# H5 register map
Vendor: Allwinner; Series: H5; File version: 0.1
CPU: 0, little endian, MPU, no FPU, 0 interrupt priority bits
Registers are 32-bit, read-write, reset 0x0 unless marked. A register's access mark holds for its fields unless they carry their own. Offsets are from the block's base; [hi:lo] are bit positions.

## CIR
Base 0x01F02000
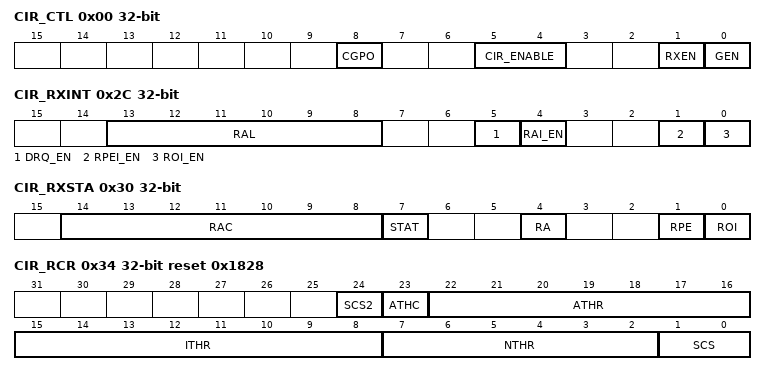
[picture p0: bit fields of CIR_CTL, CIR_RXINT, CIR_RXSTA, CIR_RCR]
0x00 CIR_CTL — CIR Control Register
  [8] CGPO — General Program Output (GPO) Control in CIR mode for TX Pin 0: Low level 1: High level
    0=Low_level; 1=High_level
  [5:4] CIR_ENABLE — 00~10: Reserved 11: CIR mode enable
    3=CIR mode enable
  [1] RXEN — Receiver Block Enable 0: Disable 1: Enable
    0=Disable; 1=Enable
  [0] GEN — Global Enable A disable on this bit overrides any other block or channel enables and flushes all FIFOs. 0: Disable 1: Enable
    0=Disable; 1=Enable
0x10 CIR_RXCTL reset 0x4 — CIR Receiver Configure Register
  [2] RPPI — Receiver Pulse Polarity Invert 0: Not invert receiver signal 1: Invert receiver signal
    0=Not invert receiver signal; 1=Invert receiver signal
0x20 CIR_RXFIFO — CIR Receiver FIFO Register
  [7:0] RECEIVER ro — Receiver Byte FIFO
0x2C CIR_RXINT — CIR Receiver Interrupt Control Register
  [13:8] RAL — RX FIFO Available Received Byte Level for interrupt and DMA request TRIGGER_LEVEL = RAL + 1
  [5] DRQ_EN — RX FIFO DMA Enable 0: Disable 1: Enable Whe set to , the Re ei e FIFO DRQ is asse ted if ea hi g RAL . The DRQ is de-asserted when condition fails.
    0=Disable; 1=Enable Whe set to , the Re ei e FIFO DRQ is asse ted if ea hi g RAL . The DRQ is de-asserted when condition fails.
  [4] RAI_EN — RX FIFO Available Interrupt Enable 0: Disable 1: Enable Whe set to , the Re ei e FIFO IRQ is asse ted if ea hi g RAL . The IRQ is de-asserted when condition fails.
    0=Disable; 1=Enable Whe set to , the Re ei e FIFO IRQ is asse ted if ea hi g RAL . The IRQ is de-asserted when condition fails.
  [1] RPEI_EN — Receiver Packet End Interrupt Enable 0: Disable 1: Enable
    0=Disable; 1=Enable
  [0] ROI_EN — Receiver FIFO Overrun Interrupt Enable 0: Disable 1: Enable
    0=Disable; 1=Enable
0x30 CIR_RXSTA — CIR Receiver Status Register
  [14:8] RAC ro — RX FIFO Available Counter 0000000: No available data in RX FIFO 0000001: 1 byte available data in RX FIFO 0000010: 2 byte available data in RX FIFO ... 1000000: 64 byte available data in RX FIFO
    0=No available data in RX FIFO; 1=1 byte available data in RX FIFO; 2=2 byte available data in RX FIFO ; 64=64 byte available data in RX FIFO
  [7] STAT ro — Status of CIR 0: Idle 1: Busy
    0=Idle; 1=Busy
  [4] RA write-1-clears — RX FIFO Available 0: RX FIFO not available according its level 1: RX FIFO available according its level This it is lea ed iti g a .
    0=RX_FIFO (RX FIFO not available according its level); 1=RX FIFO available according its level This it is lea ed iti g a 
  [1] RPE write-1-clears — Receiver Packet End Flag 0: One CIR symbol is receiving or not detected. 1: One CIR symbol is received. This it is lea ed iti g a .
    0=receiving (One CIR symbol is receiving or not detected.); 1=received (One CIR symbol is received. This it is lea ed iti g a .)
  [0] ROI write-1-clears — Receiver FIFO Overrun 0: Receiver FIFO not overrun 1: Receiver FIFO overrun This it is lea ed iti g a .
    0=Receiver_FIFO_not_overrun; 1=Receiver FIFO overrun This it is lea ed iti g a 
0x34 CIR_RCR reset 0x1828
  [24] SCS2 — Bit2 of Sample Clock Select for CIR This bit is defined by SCS bits below.
  [23] ATHC — Active Threshold Control for CIR 0: ATHR in Unit of (Sample Clock) 1: ATHR in Unit of (128*Sample Clocks)
    0=ATHR_in_Unit_of__openingparen_Sample (ATHR in Unit of (Sample Clock)); 1=ATHR_in_Unit_of__openingparen_128_times_Sample (ATHR in Unit of (128*Sample Clocks))
  [22:16] ATHR — Active Threshold for CIR These bits control the duration of CIR from Idle to Active State. The duration can be calculated by ((ATHR + 1)*(ATHC? Sample Clock: 128*Sample Clock)).
  [15:8] ITHR — Idle Threshold for CIR The Receiver uses the field to decide whether the CIR command has been received. If there is no CIR signal on the air, the receiver retains in IDLE status. One active pulse will bring the receiver from IDLE status to Receiving status. After the CIR is end, the inputting signal will keep the specified level (high or low level) for a long time. The receiver can use this idle signal duration to decide that it has received the CIR command. The corresponding flag is asserted. If the corresponding interrupt is enabled, the interrupt line is asserted to CPU. When the duration of signal keeps one status (high or low level) for the specified duration ( (ITHR + 1)*128 sample_clk ), this means that the previous CIR command has been finished.
  [7:2] NTHR — Noise Threshold for CIR When the duration of signal pulse (high or low level) is less than NTHR, the pulse is taken as noise and should be discarded by hardware. 000000: All samples are recorded into RX FIFO 000001: If the signal is only one sample duration, it is taken as noise and discarded. 000010: If the signal is less than (<=) two sample duration, it is taken as noise and discarded. ... 111101: If the signal is less than (<=) sixty-one sample duration, it is taken as noise and discarded.
  [1:0] SCS — Sample Clock Select for CIR SCS2 SCS[1] SCS[0] Sample Clock 0 0 0 ir_clk/64 0 0 1 ir_clk/128 0 1 0 ir_clk/256 0 1 1 ir_clk/512 1 0 0 ir_clk 1 0 1 Reserved 1 1 0 Reserved 1 1 1 Reserved
